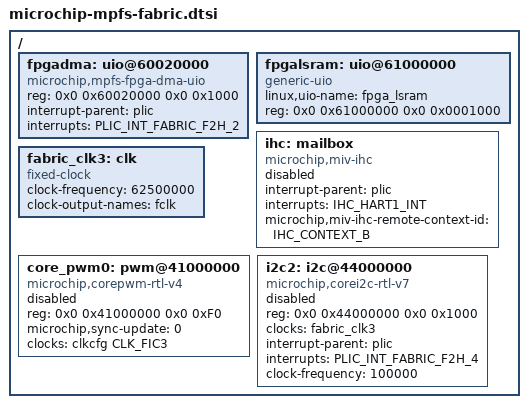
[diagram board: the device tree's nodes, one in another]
// SPDX-License-Identifier: (GPL-2.0 OR MIT)
/* Copyright (c) 2020-2021 Microchip Technology Inc */

/ {
	fpgadma: uio@60020000 {
		compatible = "microchip,mpfs-fpga-dma-uio";
		#address-cells = <1>;
		#size-cells = <0>;
		reg = <0x0 0x60020000 0x0 0x1000>;
		interrupt-parent = <&plic>;
		interrupts = <PLIC_INT_FABRIC_F2H_2>;
		status = "okay";
	};

	fpgalsram: uio@61000000 {
		compatible = "generic-uio";
		linux,uio-name = "fpga_lsram";
		reg = <0x0 0x61000000 0x0 0x0001000>;
		status = "okay";
	};

	ihc: mailbox {
		compatible = "microchip,miv-ihc";
		interrupt-parent = <&plic>;
		interrupts = <IHC_HART1_INT>;
		microchip,miv-ihc-remote-context-id = <IHC_CONTEXT_B>;
		#mbox-cells = <1>;
		status = "disabled";
	};

	fabric_clk3: clk {
		compatible = "fixed-clock";
		#clock-cells = <0>;
		clock-frequency = <62500000>;
		clock-output-names = "fclk";
	};

	core_pwm0: pwm@41000000 {
		compatible = "microchip,corepwm-rtl-v4";
		reg = <0x0 0x41000000 0x0 0xF0>;
		microchip,sync-update = /bits/ 16 <0>;
		clocks = <&clkcfg CLK_FIC3>;
		#pwm-cells = <2>;
		status = "disabled";
	};

	i2c2: i2c@44000000 {
		compatible = "microchip,corei2c-rtl-v7";
		reg = <0x0 0x44000000 0x0 0x1000>;
		#address-cells = <1>;
		#size-cells = <0>;
		clocks = <&fabric_clk3>;
		interrupt-parent = <&plic>;
		interrupts = <PLIC_INT_FABRIC_F2H_4>;
		clock-frequency = <100000>;
		status = "disabled";
	};
};
